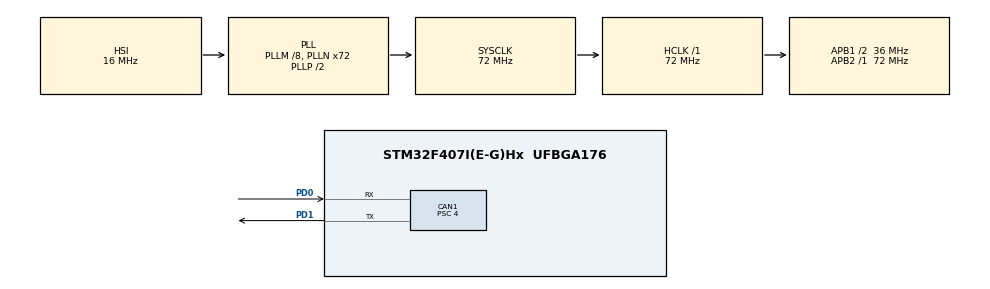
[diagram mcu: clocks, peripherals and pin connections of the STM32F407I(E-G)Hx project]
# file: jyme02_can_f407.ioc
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CAN1.BS1=CAN_BS1_5TQ
CAN1.BS2=CAN_BS2_3TQ
CAN1.CalculateBaudRate=1000000
CAN1.CalculateTimeBit=1000
CAN1.CalculateTimeQuantum=111.11111111111111
CAN1.Prescaler=4
Mcu.Family=STM32F4
Mcu.Name=STM32F407I(E-G)Hx
Mcu.Package=UFBGA176
NVIC.CAN1_RX0_IRQn=true\:0\:0\:false\:false\:true\:true\:true\:true
NVIC.PriorityGroup=NVIC_PRIORITYGROUP_4
PA13.Mode=Serial_Wire
PA13.Signal=SYS_JTMS-SWDIO
PA14.Mode=Serial_Wire
PA14.Signal=SYS_JTCK-SWCLK
PD0.Mode=CAN_Activate
PD0.Signal=CAN1_RX
PD1.Mode=CAN_Activate
PD1.Signal=CAN1_TX
PH0-OSC_IN.Mode=HSE-External-Oscillator
PH0-OSC_IN.Signal=RCC_OSC_IN
PH1-OSC_OUT.Mode=HSE-External-Oscillator
PH1-OSC_OUT.Signal=RCC_OSC_OUT
ProjectManager.HeapSize=0x200
ProjectManager.StackSize=0x400
ProjectManager.TargetToolchain=MDK-ARM V5.32
RCC.48MHZClocksFreq_Value=36000000
RCC.AHBFreq_Value=72000000
RCC.APB1CLKDivider=RCC_HCLK_DIV2
RCC.APB1Freq_Value=36000000
RCC.APB1TimFreq_Value=72000000
RCC.APB2Freq_Value=72000000
RCC.APB2TimFreq_Value=72000000
RCC.CortexFreq_Value=72000000
RCC.HCLKFreq_Value=72000000
RCC.HSE_VALUE=12000000
RCC.HSI_VALUE=16000000
RCC.LSE_VALUE=32768
RCC.PLLM=8
RCC.PLLN=72
RCC.SYSCLKFreq_VALUE=72000000
RCC.SYSCLKSource=RCC_SYSCLKSOURCE_PLLCLK
RCC.VCOOutputFreq_Value=144000000
board=custom

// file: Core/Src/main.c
/* USER CODE BEGIN Header */
/**
 ******************************************************************************
 * @file           : main.c
 * @brief          : Main program body
 ******************************************************************************
 * @attention
 *
 * Copyright (c) 2023 STMicroelectronics.
 * All rights reserved.
 *
 * This software is licensed under terms that can be found in the LICENSE file
 * in the root directory of this software component.
 * If no LICENSE file comes with this software, it is provided AS-IS.
 *
 ******************************************************************************
 */
/* USER CODE END Header */
#include "main.h"

/* USER CODE BEGIN Includes */
#include "..\..\JYME02-CAN-Core\jyme02_can.hpp"
/* USER CODE END Includes */

CAN_HandleTypeDef hcan1;

void SystemClock_Config(void);
static void MX_GPIO_Init(void);
static void MX_CAN1_Init(void);

int main(void)
{

  /* MCU Configuration--------------------------------------------------------*/

  /* Reset of all peripherals, Initializes the Flash interface and the Systick. */
  HAL_Init();

  /* Configure the system clock */
  SystemClock_Config();

  /* Initialize all configured peripherals */
  MX_GPIO_Init();
  MX_CAN1_Init();
  /* USER CODE BEGIN 2 */

    Jyme02_Can_Init(&hcan1, CAN_FILTER_FIFO0);
  /* USER CODE END 2 */

  /* Infinite loop */
  /* USER CODE BEGIN WHILE */
    while (1) {
        HAL_Delay(100);
        Jyme02_Can_Set_Mode(0x50, JYME02_MODE_SINGLE);
        // Jyme02_Can_Read_AngleMode(NULL);
    /* USER CODE END WHILE */

    }
}

void SystemClock_Config(void)
{
  RCC_OscInitTypeDef RCC_OscInitStruct = {0};
  RCC_ClkInitTypeDef RCC_ClkInitStruct = {0};

  /** Configure the main internal regulator output voltage
  */
  __HAL_RCC_PWR_CLK_ENABLE();
  __HAL_PWR_VOLTAGESCALING_CONFIG(PWR_REGULATOR_VOLTAGE_SCALE1);

  /** Initializes the RCC Oscillators according to the specified parameters
  * in the RCC_OscInitTypeDef structure.
  */
  RCC_OscInitStruct.OscillatorType = RCC_OSCILLATORTYPE_HSI;
  RCC_OscInitStruct.HSIState = RCC_HSI_ON;
  RCC_OscInitStruct.HSICalibrationValue = RCC_HSICALIBRATION_DEFAULT;
  RCC_OscInitStruct.PLL.PLLState = RCC_PLL_ON;
  RCC_OscInitStruct.PLL.PLLSource = RCC_PLLSOURCE_HSI;
  RCC_OscInitStruct.PLL.PLLM = 8;
  RCC_OscInitStruct.PLL.PLLN = 72;
  RCC_OscInitStruct.PLL.PLLP = RCC_PLLP_DIV2;
  RCC_OscInitStruct.PLL.PLLQ = 4;
  if (HAL_RCC_OscConfig(&RCC_OscInitStruct) != HAL_OK)
  {
    Error_Handler();
  }

  /** Initializes the CPU, AHB and APB buses clocks
  */
  RCC_ClkInitStruct.ClockType = RCC_CLOCKTYPE_HCLK|RCC_CLOCKTYPE_SYSCLK
                              |RCC_CLOCKTYPE_PCLK1|RCC_CLOCKTYPE_PCLK2;
  RCC_ClkInitStruct.SYSCLKSource = RCC_SYSCLKSOURCE_PLLCLK;
  RCC_ClkInitStruct.AHBCLKDivider = RCC_SYSCLK_DIV1;
  RCC_ClkInitStruct.APB1CLKDivider = RCC_HCLK_DIV2;
  RCC_ClkInitStruct.APB2CLKDivider = RCC_HCLK_DIV1;

  if (HAL_RCC_ClockConfig(&RCC_ClkInitStruct, FLASH_LATENCY_2) != HAL_OK)
  {
    Error_Handler();
  }
}

static void MX_CAN1_Init(void)
{

  hcan1.Instance = CAN1;
  hcan1.Init.Prescaler = 4;
  hcan1.Init.Mode = CAN_MODE_NORMAL;
  hcan1.Init.SyncJumpWidth = CAN_SJW_1TQ;
  hcan1.Init.TimeSeg1 = CAN_BS1_5TQ;
  hcan1.Init.TimeSeg2 = CAN_BS2_3TQ;
  hcan1.Init.TimeTriggeredMode = DISABLE;
  hcan1.Init.AutoBusOff = DISABLE;
  hcan1.Init.AutoWakeUp = DISABLE;
  hcan1.Init.AutoRetransmission = DISABLE;
  hcan1.Init.ReceiveFifoLocked = DISABLE;
  hcan1.Init.TransmitFifoPriority = DISABLE;
  if (HAL_CAN_Init(&hcan1) != HAL_OK)
  {
    Error_Handler();
  }

}

static void MX_GPIO_Init(void)
{

  /* GPIO Ports Clock Enable */
  __HAL_RCC_GPIOA_CLK_ENABLE();
  __HAL_RCC_GPIOD_CLK_ENABLE();
  __HAL_RCC_GPIOH_CLK_ENABLE();

}

/* USER CODE BEGIN 4 */

void HAL_CAN_RxFifo0MsgPendingCallback(CAN_HandleTypeDef *hcan)
{
    /* Prevent unused argument(s) compilation warning */
    float angle;
    uint16_t addr;
    if (hcan->Instance == CAN1) {
        angle = Jyme02_Can_Read_AngleMode(&addr);
    }
    /* NOTE : This function Should not be modified, when the callback is needed,
              the HAL_CAN_TxMailbox0AbortCallback could be implemented in the
              user file
     */
}
/* USER CODE END 4 */

void Error_Handler(void)
{
    __disable_irq();
    while (1) {
    }
}
